# M462 register map
File version: 0.1
Registers are 32-bit, read-write, reset 0x0 unless marked. A register's access mark holds for its fields unless they carry their own. Offsets are from the block's base; [hi:lo] are bit positions; {n}, {i} and the like mark numbered series.

## CG — Clock Generator (CG)
Base 0x403F3000
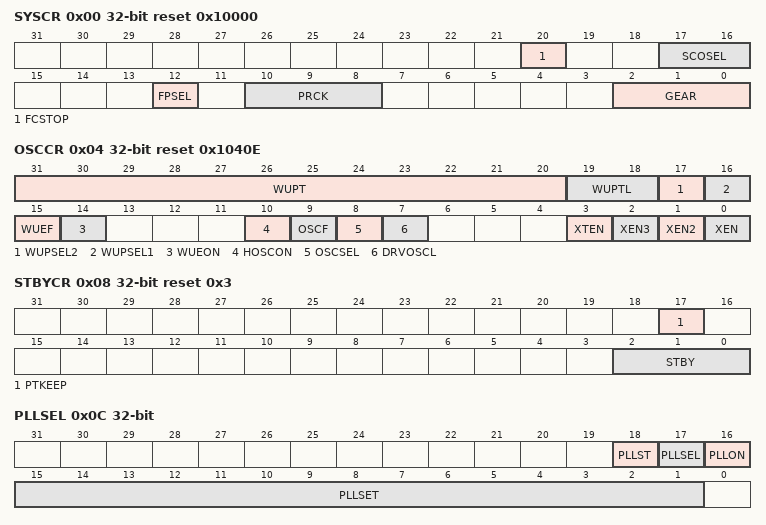
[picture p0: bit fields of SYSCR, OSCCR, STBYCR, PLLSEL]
0x00 SYSCR reset 0x10000 — System Control Register
  [20] FCSTOP, [17:16] SCOSEL, [12] FPSEL, [10:8] PRCK, [2:0] GEAR
0x04 OSCCR reset 0x1040E — Oscillation Control Register
  [31:20] WUPT, [19:18] WUPTL, [17] WUPSEL2, [16] WUPSEL1, [15] WUEF, [14] WUEON, [10] HOSCON, [9] OSCF, [8] OSCSEL, [7] DRVOSCL, [3] XTEN, [2] XEN3, [1] XEN2, [0] XEN
0x08 STBYCR reset 0x3 — Standby Control Register
  [17] PTKEEP, [2:0] STBY
0x0C PLLSEL — PLL Selection Register
  [18] PLLST ro, [17] PLLSEL, [16] PLLON, [15:1] PLLSET
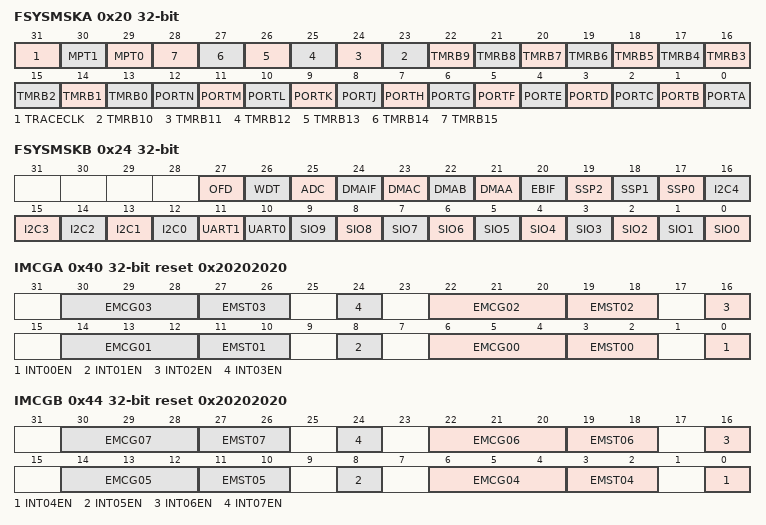
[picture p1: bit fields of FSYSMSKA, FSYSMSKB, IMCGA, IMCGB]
0x20 FSYSMSKA — fclk Supply Stop Register A
  [31] TRACECLK, [30] MPT1, [29] MPT0, [n+13] TMRB{n} (n=0..15), [12] PORTN, [11] PORTM, [10] PORTL, [9] PORTK, [8] PORTJ, [7] PORTH, [6] PORTG, [5] PORTF, [4] PORTE, [3] PORTD, [2] PORTC, [1] PORTB, [0] PORTA
0x24 FSYSMSKB — fclk Supply Stop Register B
  [27] OFD, [26] WDT, [25] ADC, [24] DMAIF, [23] DMAC, [22] DMAB, [21] DMAA, [20] EBIF, [19] SSP2, [18] SSP1, [17] SSP0, [n+12] I2C{n} (n=0..4), [11] UART1, [10] UART0, [n] SIO{n} (n=0..9)
0x3C PROTECT reset 0xC1
  [7:0] CGPROTECT
0x40 IMCGA reset 0x20202020 — CG Interrupt Mode Control Register A
  [8n+6:8n+4] EMCG{n:02} (n=0..3), [8n+3:8n+2] EMST{n:02} ro (n=0..3), [8n] INT{n:02}EN (n=0..3)
0x44 IMCGB reset 0x20202020 — CG Interrupt Mode Control Register B
  [8n-26:8n-28] EMCG{n:02} (n=4..7), [8n-29:8n-30] EMST{n:02} ro (n=4..7), [8n-32] INT{n:02}EN (n=4..7)
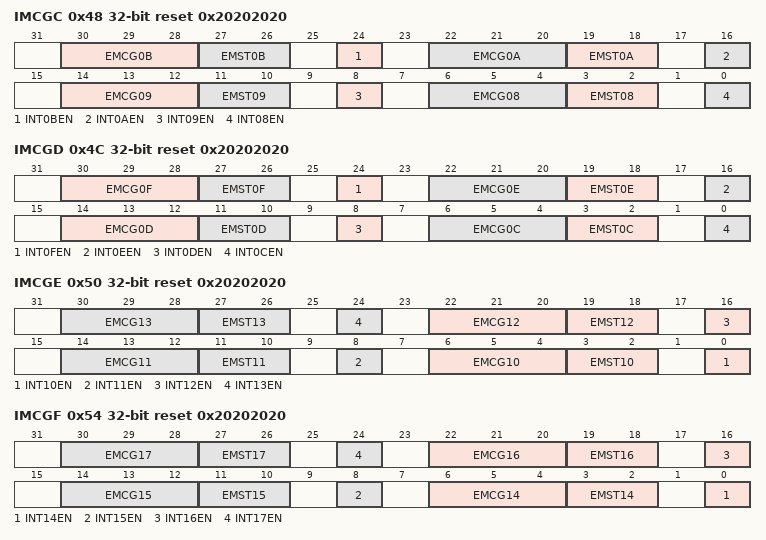
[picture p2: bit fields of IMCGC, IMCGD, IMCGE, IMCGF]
0x48 IMCGC reset 0x20202020 — CG Interrupt Mode Control Register C
  [30:28] EMCG0B, [27:26] EMST0B ro, [24] INT0BEN, [22:20] EMCG0A, [19:18] EMST0A ro, [16] INT0AEN, [14:12] EMCG09, [11:10] EMST09 ro, [8] INT09EN, [6:4] EMCG08, [3:2] EMST08 ro, [0] INT08EN
0x4C IMCGD reset 0x20202020 — CG Interrupt Mode Control Register D
  [30:28] EMCG0F, [27:26] EMST0F ro, [24] INT0FEN, [22:20] EMCG0E, [19:18] EMST0E ro, [16] INT0EEN, [14:12] EMCG0D, [11:10] EMST0D ro, [8] INT0DEN, [6:4] EMCG0C, [3:2] EMST0C ro, [0] INT0CEN
0x50 IMCGE reset 0x20202020 — CG Interrupt Mode Control Register E
  [8n-74:8n-76] EMCG{n} (n=10..13), [8n-77:8n-78] EMST{n} ro (n=10..13), [8n-80] INT{n}EN (n=10..13)
0x54 IMCGF reset 0x20202020 — CG Interrupt Mode Control Register F
  [8n-106:8n-108] EMCG{n} (n=14..17), [8n-109:8n-110] EMST{n} ro (n=14..17), [8n-112] INT{n}EN (n=14..17)
0x60 ICRCG wo — CG Interrupt Request Clear Register
  [4:0] ICRCG
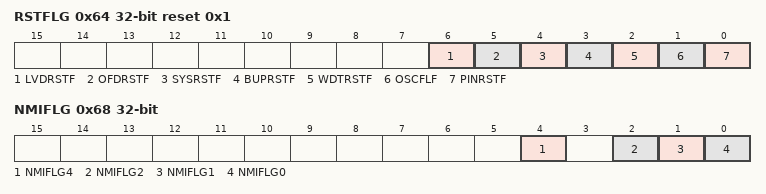
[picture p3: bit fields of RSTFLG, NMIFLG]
0x64 RSTFLG reset 0x1 — Reset Flag Register
  [6] LVDRSTF, [5] OFDRSTF ro, [4] SYSRSTF, [3] BUPRSTF, [2] WDTRSTF, [1] OSCFLF ro, [0] PINRSTF
0x68 NMIFLG ro — NMI Flag Register
  [4] NMIFLG4, [2] NMIFLG2, [1] NMIFLG1, [0] NMIFLG0

## LVD — Low voltage detecter
Base 0x403F4000
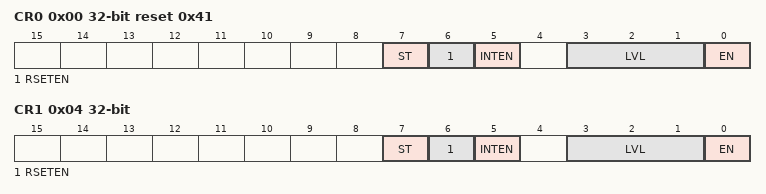
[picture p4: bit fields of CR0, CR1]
0x00 CR0 reset 0x41 — LVD-RVDD3 detection control register0
  [7] ST ro, [6] RSETEN, [5] INTEN, [3:1] LVL, [0] EN
0x04 CR1 — LVD-RVDD3 detection control register1
  [7] ST ro, [6] RSETEN, [5] INTEN, [3:1] LVL, [0] EN

## FC — Flash Control (FC)
Base 0x41FFF000
0x10 SECBIT reset 0x1 — Security Bit Register
  [0] SECBIT
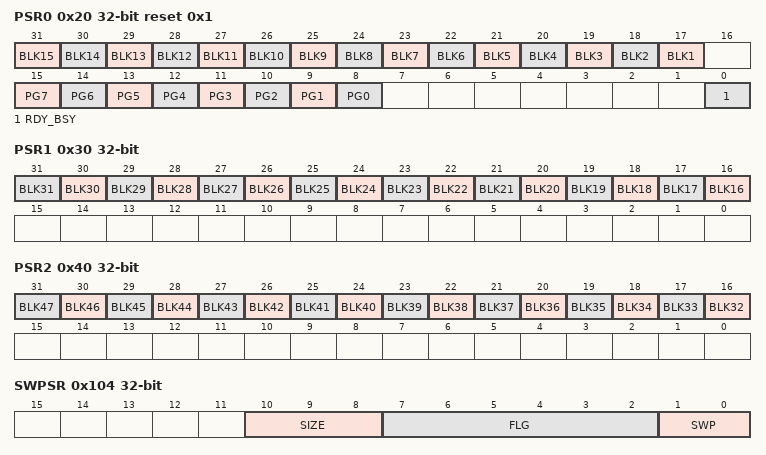
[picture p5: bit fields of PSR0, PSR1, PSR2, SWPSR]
0x20 PSR0 ro reset 0x1 (reset mask 0xFF) — Protect Status Register 0
  [n+16] BLK{n} (n=1..15), [n+8] PG{n} (n=0..7), [0] RDY_BSY
0x30 PSR1 ro (reset mask 0xFFFE) — Protect Status Register 1
  [n] BLK{n} (n=16..31)
0x40 PSR2 ro (reset mask 0xFFFE) — Protect Status Register 2
  [n-16] BLK{n} (n=32..47)
0x100 SR ro reset 0x1 — Status Register
  [24] WEABORT
0x104 SWPSR ro (reset mask 0xFFFFF800) — Swap Status Register
  [10:8] SIZE, [7:2] FLG, [1:0] SWP
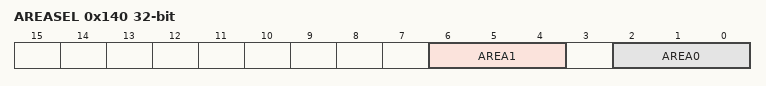
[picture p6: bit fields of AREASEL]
0x140 AREASEL — Area Selection Register
  [6:4] AREA1, [2:0] AREA0
0x148 CR — Control Register
  [2:0] WEABORT
0x14C STSCLR — Status Clear Register
  [2:0] WEABORT
0x150 WCLKCR — WCLK Configuration Register
  [4:0] DIV
0x154 PROGCR reset 0x1 — Program Counter Configuration Register
  [1:0] CNT
0x158 ERASECR reset 0x6 — Erase Counter Configuration Register
  [3:0] CNT
